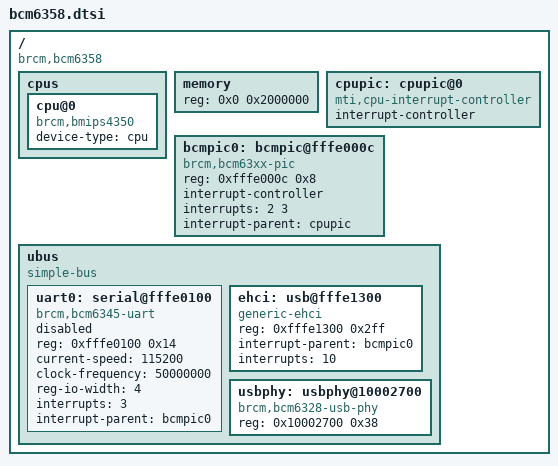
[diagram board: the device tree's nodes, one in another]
/ {
	#address-cells = <1>;
	#size-cells = <1>;
	compatible = "brcm,bcm6358";
	cpus {
		cpu@0 {
			device-type = "cpu";
			compatible = "brcm,bmips4350";
		};
	};
	memory {
		device_type = "memory";
		reg = <0x0 0x2000000>;
	};
	cpupic: cpupic@0 {
		#address-cells = <0>;
		#interrupt-cells = <1>;
		interrupt-controller;
		compatible = "mti,cpu-interrupt-controller";
	};
	bcmpic0: bcmpic@fffe000c {
		#interrupt-cells = <1>;
		reg = <0xfffe000c 0x8>;
		interrupt-controller;
		interrupts = <2 3>;
		interrupt-parent = <&cpupic>;
		compatible = "brcm,bcm63xx-pic";
	};
	ubus {
		#address-cells = <1>;
		#size-cells = <1>;
		#interrupt-cells = <1>;
		compatible = "simple-bus";
		ranges = <0xfffe0000 0xfffe0fff>;
		uart0: serial@fffe0100 {
			compatible = "brcm,bcm6345-uart";
			reg = <0xfffe0100 0x14>;
			current-speed = <115200>;
			clock-frequency = <50000000>;
			reg-io-width = <4>;
			interrupts = <3>;
			interrupt-parent = <&bcmpic0>;
			status = "disabled";
		};
		ehci: usb@fffe1300 {
			compatible = "generic-ehci";
			reg = <0xfffe1300 0x2ff>;
			interrupt-parent = <&bcmpic0>;
			interrupts = <10>;
		};
/*		ohci: usb@10002600 { 
			compatible = "generic-ohci";
			reg = <0x10002600 0x100>;
			big-endian;
			interrupts = <41>;
			interrupt-parent = <&bcmpic0>;
			phys = <&usbphy 0>;
			phy-names = "usb";
		};*/
		usbphy: usbphy@10002700 {
			#phy-cells = <0>;
			compatible = "brcm,bcm6328-usb-phy";
			reg = <0x10002700 0x38>;
		};
	};
};
